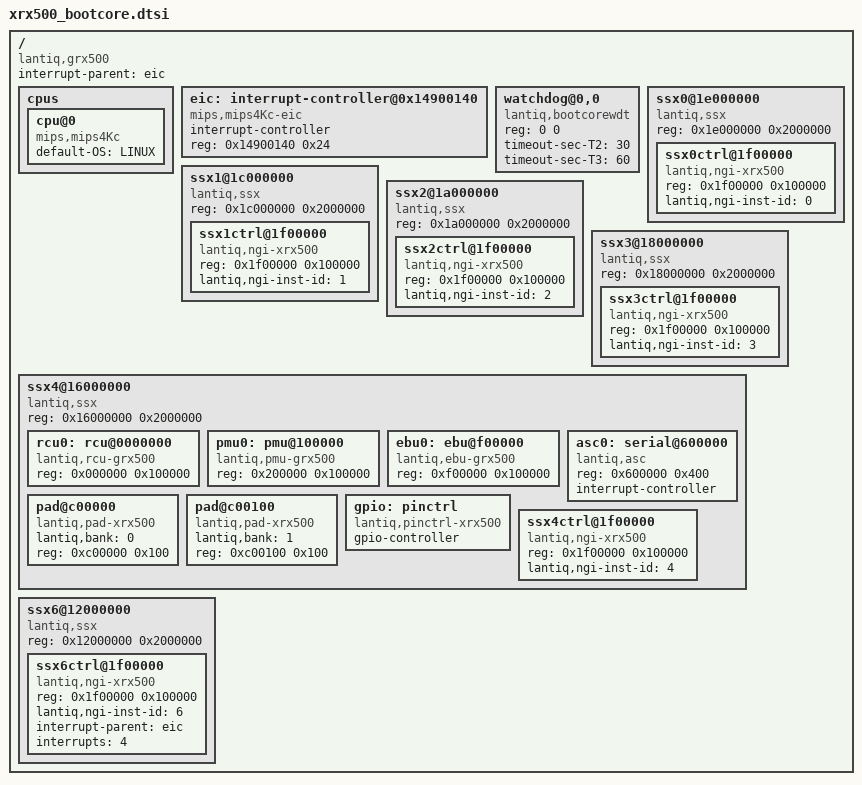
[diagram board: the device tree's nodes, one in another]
/ {
	#address-cells = <1>;
	#size-cells = <1>;
	compatible = "lantiq,grx500";  
    interrupt-parent = <&eic>;

	cpus {
		cpu@0 {
			compatible = "mips,mips4Kc";
			default-OS = "LINUX";
		};
	
	};

    eic: interrupt-controller@0x14900140 {
        compatible = "mips,mips4Kc-eic";
        #interrupt-cells = <1>;
        #address-cells = <0>;
        interrupt-controller;
        reg = <0x14900140 0x24>;
    };

	watchdog@0,0 {
		compatible = "lantiq,bootcorewdt","lantiq, wdt-bootcore-xrx500"; 
		reg = <0 0>;
		timeout-sec-T2 = <30>;
		timeout-sec-T3 = <60>;
	};

	ssx0@1e000000 {
		#address-cells = <1>;
		#size-cells = <1>;
		compatible = "lantiq,ssx", "simple-bus";
		reg = <0x1e000000 0x2000000>;
		ranges = <0x0 0x1e000000 0x02000000>;

		ssx0ctrl@1f00000 {
			#address-cells = <1>;
			#size-cells = <1>;
			compatible = "lantiq,ngi-xrx500";
			reg = <0x1f00000 0x100000>;
			/*ranges = <0x0 0x1f00000 0x0100000>;*/
			lantiq,ngi-inst-id = <0>;
		};
	};

	ssx1@1c000000 {
		#address-cells = <1>;
		#size-cells = <1>;
		compatible = "lantiq,ssx", "simple-bus";
		reg = <0x1c000000 0x2000000>;
		ranges = <0x0 0x1c000000 0x02000000>;

		ssx1ctrl@1f00000 {
			#address-cells = <1>;
			#size-cells = <1>;
			compatible = "lantiq,ngi-xrx500";
			reg = <0x1f00000 0x100000>;
			/*ranges = <0x0 0x1f00000 0x0100000>;*/
			lantiq,ngi-inst-id = <1>;
		};
	};

	ssx2@1a000000 {
		#address-cells = <1>;
		#size-cells = <1>;
		compatible = "lantiq,ssx", "simple-bus";
		reg = <0x1a000000 0x2000000>;
		ranges = <0x0 0x1a000000 0x02000000>;

		ssx2ctrl@1f00000 {
			#address-cells = <1>;
			#size-cells = <1>;
			compatible = "lantiq,ngi-xrx500";
			reg = <0x1f00000 0x100000>;
			/*ranges = <0x0 0x1f00000 0x0100000>;*/
			lantiq,ngi-inst-id = <2>;
		};
	};

	ssx3@18000000 {
		#address-cells = <1>;
		#size-cells = <1>;
		compatible = "lantiq,ssx", "simple-bus";
		reg = <0x18000000 0x2000000>;
		ranges = <0x0 0x18000000 0x02000000>;

		ssx3ctrl@1f00000 {
			#address-cells = <1>;
			#size-cells = <1>;
			compatible = "lantiq,ngi-xrx500";
			reg = <0x1f00000 0x100000>;
			ranges = <0x0 0x1f00000 0x0100000>;
			lantiq,ngi-inst-id = <3>;
		};
	};

	ssx4@16000000 {
		#address-cells = <1>;
		#size-cells = <1>;
		compatible = "lantiq,ssx", "simple-bus";
		reg = <0x16000000 0x2000000>;
		ranges = <0x0 0x16000000 0x02000000>;

		rcu0: rcu@0000000 {
			compatible = "lantiq,rcu-grx500";
			reg = <0x000000 0x100000>;
		};

		pmu0: pmu@100000 {
			compatible = "lantiq,pmu-grx500";
			reg = <0x200000 0x100000>;
		};

		ebu0: ebu@f00000 {
			compatible = "lantiq,ebu-grx500";
			reg = <0xf00000 0x100000>;
			reg-names = "ebunand_reg", "hsnand_reg";
		};

                asc0: serial@600000 {
                        compatible = "lantiq,asc";
                        reg = <0x600000 0x400>;
                        interrupt-controller;
                };

		pad@c00000{
			compatible = "lantiq,pad-xrx500";
			lantiq,bank = <0>;
			reg = <0xc00000 0x100>;
		};

		pad@c00100{
			compatible = "lantiq,pad-xrx500";
			lantiq,bank = <1>;
			reg = <0xc00100 0x100>;
		};

		gpio: pinctrl {
			compatible = "lantiq,pinctrl-xrx500";
			pinctrl-names = "default";
			#gpio-cells = <2>;
			gpio-controller;
			
		};

		ssx4ctrl@1f00000 {
			#address-cells = <1>;
			#size-cells = <1>;
			compatible = "lantiq,ngi-xrx500";
			reg = <0x1f00000 0x100000>;
			/*ranges = <0x0 0x1f00000 0x0100000>;*/
			lantiq,ngi-inst-id = <4>;
		};
	};

	ssx6@12000000 {
		#address-cells = <1>;
		#size-cells = <1>;
		compatible = "lantiq,ssx", "simple-bus";
		reg = <0x12000000 0x2000000>;
		ranges = <0x0 0x12000000 0x02000000>;

		ssx6ctrl@1f00000 {
			#address-cells = <1>;
			#size-cells = <1>;
			compatible = "lantiq,ngi-xrx500";
			reg = <0x1f00000 0x100000>;
			/*ranges = <0x0 0x13f00000 0x0100000>;*/
			lantiq,ngi-inst-id = <6>;
			interrupt-parent = <&eic>;
			interrupts = <4>;
		
		};
	};

};
